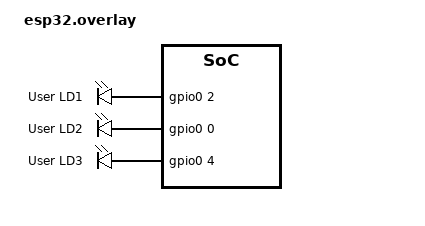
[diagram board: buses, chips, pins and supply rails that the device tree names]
/ {
       leds {
		compatible = "gpio-leds";
		external_led_1: led_1 {
			gpios = <&gpio0 2 GPIO_ACTIVE_HIGH>;
			label = "User LD1";
		};

		external_led_2: led_2 {
			gpios = <&gpio0 0 GPIO_ACTIVE_HIGH>;
			label = "User LD2";
		};

		external_led_3: led_3 {
			gpios = <&gpio0 4 GPIO_ACTIVE_HIGH>;
			label = "User LD3";
		};
		
	};

	aliases {
		led0 = &external_led_1;
		led1 = &external_led_2;
		led2 = &external_led_3;

	};
};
